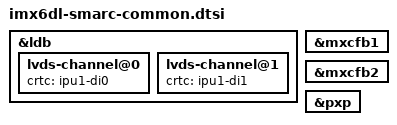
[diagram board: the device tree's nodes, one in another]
/*
 * Copyright (C) 2014 Freescale Semiconductor, Inc.
 *
 * This program is free software; you can redistribute it and/or modify
 * it under the terms of the GNU General Public License version 2 as
 * published by the Free Software Foundation.
 */

&ldb {
	lvds-channel@0 {
		crtc = "ipu1-di0";
	};

	lvds-channel@1 {
		crtc = "ipu1-di1";
	};
};

&mxcfb1 {
	status = "okay";
};

&mxcfb2 {
	status = "okay";
};

&pxp {
	status = "okay";
};
